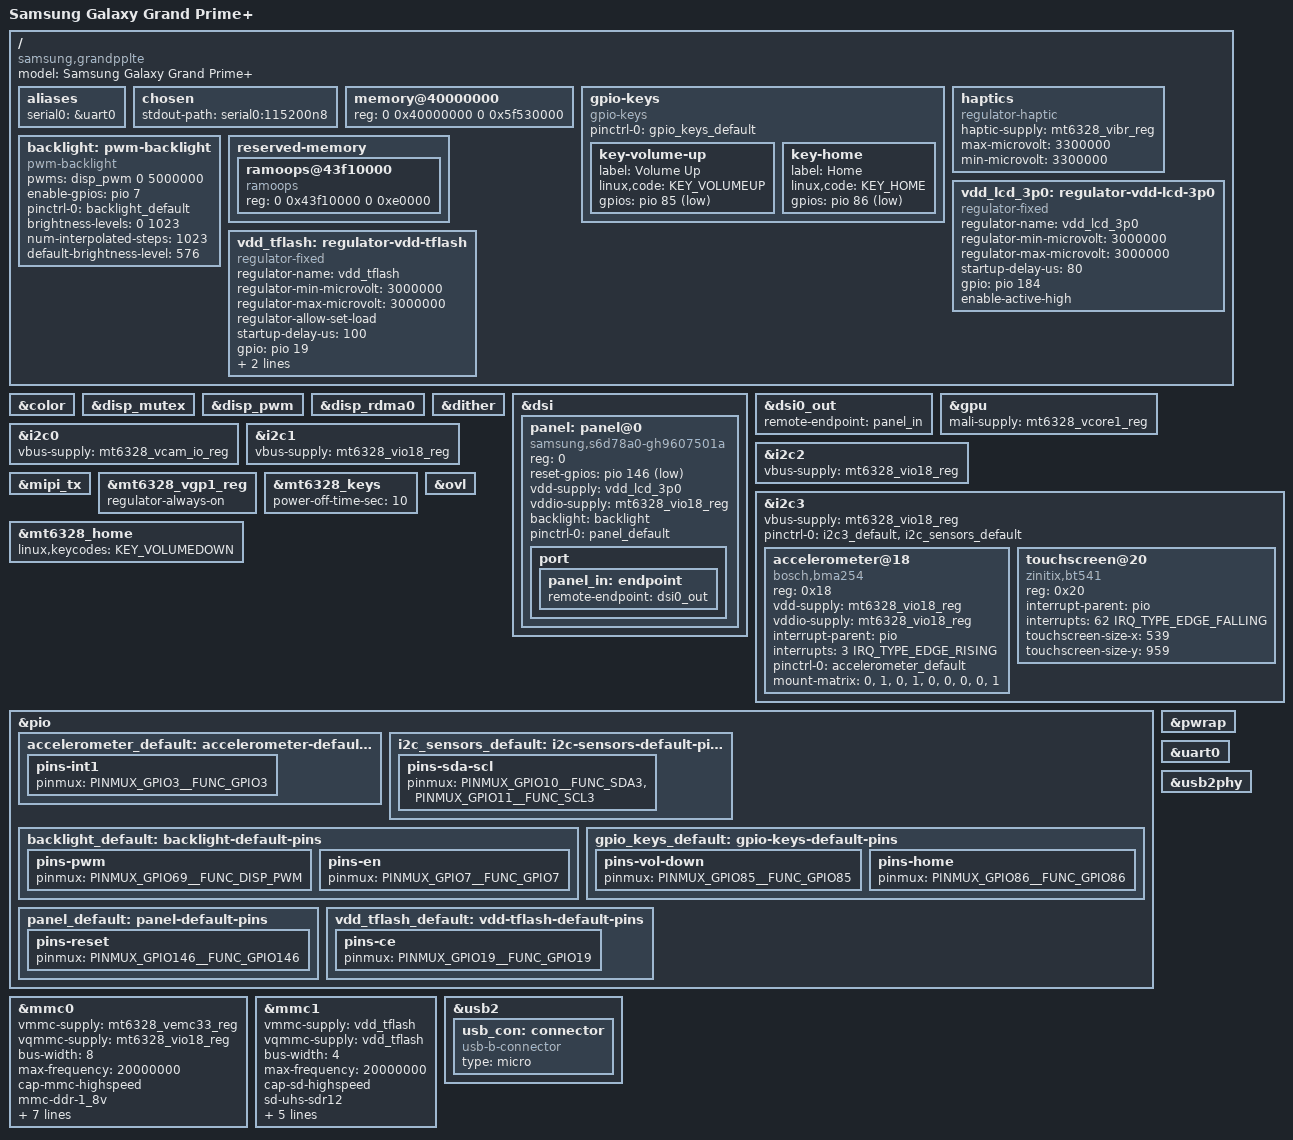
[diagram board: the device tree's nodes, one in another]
// SPDX-License-Identifier: BSD-3-Clause
/*
 * Copyright (c) 2021, Yassine Oudjana <y.oudjana@protonmail.com>
 */

/dts-v1/;

#include "mt6735.dtsi"
#include "mt6328.dtsi"
#include <dt-bindings/gpio/gpio.h>
#include <dt-bindings/input/input.h>
#include <dt-bindings/pinctrl/mediatek,mt6735-pinctrl.h>

/ {
	model = "Samsung Galaxy Grand Prime+";
	compatible = "samsung,grandpplte",
		     "mediatek,mt6737t",
		     "mediatek,mt6735";

	aliases {
		serial0 = &uart0;
	};

	chosen {
		#address-cells = <2>;
		#size-cells = <2>;
		ranges;

		stdout-path = "serial0:115200n8";
	};

	memory@40000000 {
		device_type = "memory";
		reg = <0 0x40000000 0 0x5f530000>;
	};

	gpio-keys {
		compatible = "gpio-keys";

		pinctrl-names = "default";
		pinctrl-0 = <&gpio_keys_default>;

		key-volume-up {
			label = "Volume Up";
			linux,code = <KEY_VOLUMEUP>;
			gpios = <&pio 85 GPIO_ACTIVE_LOW>;
		};

		key-home {
			label = "Home";
			linux,code = <KEY_HOME>;
			gpios = <&pio 86 GPIO_ACTIVE_LOW>;
		};
	};

	haptics {
		compatible = "regulator-haptic";
		haptic-supply = <&mt6328_vibr_reg>;
		max-microvolt = <3300000>;
		min-microvolt = <3300000>;
	};

	backlight: pwm-backlight {
		compatible = "pwm-backlight";

		pwms = <&disp_pwm 0 5000000>;
		enable-gpios = <&pio 7 GPIO_ACTIVE_HIGH>;

		pinctrl-names = "default";
		pinctrl-0 = <&backlight_default>;

		brightness-levels = <0 1023>;
		num-interpolated-steps = <1023>;
		default-brightness-level = <576>;
	};

	reserved-memory {
		ramoops@43f10000 {
			compatible = "ramoops";
			reg = <0 0x43f10000 0 0xe0000>;
		};
	};

	vdd_lcd_3p0: regulator-vdd-lcd-3p0 {
		compatible = "regulator-fixed";
		regulator-name = "vdd_lcd_3p0";
		regulator-min-microvolt = <3000000>;
		regulator-max-microvolt = <3000000>;
		startup-delay-us = <80>;
		gpio = <&pio 184 0>;
		enable-active-high;
	};

	vdd_tflash: regulator-vdd-tflash {
		compatible = "regulator-fixed";
		regulator-name = "vdd_tflash";
		regulator-min-microvolt = <3000000>;
		regulator-max-microvolt = <3000000>;
		regulator-allow-set-load;
		startup-delay-us = <100>;
		gpio = <&pio 19 0>;
		enable-active-high;

		pinctrl-names = "default";
		pinctrl-0 = <&vdd_tflash_default>;
	};
};

&color {
	status = "okay";
};

&disp_mutex {
	status = "okay";
};

&disp_pwm {
	status = "okay";
};

&disp_rdma0 {
	status = "okay";
};

&dither {
	status = "okay";
};

&dsi {
	status = "okay";

	panel: panel@0 {
		compatible = "samsung,s6d78a0-gh9607501a";
		reg = <0>;

		reset-gpios = <&pio 146 GPIO_ACTIVE_LOW>;

		vdd-supply = <&vdd_lcd_3p0>;
		vddio-supply = <&mt6328_vio18_reg>;

		backlight = <&backlight>;

		pinctrl-names = "default";
		pinctrl-0 = <&panel_default>;

		port {
			panel_in: endpoint {
				remote-endpoint = <&dsi0_out>;
			};
		};
	};
};

&dsi0_out {
	remote-endpoint = <&panel_in>;
};

&gpu {
	status = "okay";

	mali-supply = <&mt6328_vcore1_reg>;
};

&i2c0 {
	status = "okay";

	vbus-supply = <&mt6328_vcam_io_reg>;
};

&i2c1 {
	status = "okay";

	vbus-supply = <&mt6328_vio18_reg>;
};

&i2c2 {
	status = "okay";

	vbus-supply = <&mt6328_vio18_reg>;
};

&i2c3 {
	status = "okay";

	vbus-supply = <&mt6328_vio18_reg>;

	pinctrl-names = "default";
	pinctrl-0 = <&i2c3_default>, <&i2c_sensors_default>;

	accelerometer@18 {
		compatible = "bosch,bma254";
		reg = <0x18>;

		vdd-supply = <&mt6328_vio18_reg>;
		vddio-supply = <&mt6328_vio18_reg>;

		interrupt-parent = <&pio>;
		interrupts = <3 IRQ_TYPE_EDGE_RISING>;
		interrupt-names = "INT1";

		pinctrl-names = "default";
		pinctrl-0 = <&accelerometer_default>;

		mount-matrix = "0", "1", "0",
				"1", "0", "0",
				"0", "0", "1";
	};

	touchscreen@20 {
		compatible = "zinitix,bt541";
		reg = <0x20>;
		interrupt-parent = <&pio>;
		interrupts = <62 IRQ_TYPE_EDGE_FALLING>;

		touchscreen-size-x = <539>;
		touchscreen-size-y = <959>;
	};
};

&mipi_tx {
	status = "okay";
};

/* Touchscreen supply. TODO: Add regulator handling to zinitix driver */
&mt6328_vgp1_reg {
	regulator-always-on;
};

&mt6328_keys {
	status = "okay";

	power-off-time-sec = <10>;
};

&mt6328_home {
	linux,keycodes = <KEY_VOLUMEDOWN>;
};

&ovl {
	status = "okay";
};

&pio {
	accelerometer_default: accelerometer-default-pins {
		pins-int1 {
			pinmux = <PINMUX_GPIO3__FUNC_GPIO3>;
		};
	};

	i2c_sensors_default: i2c-sensors-default-pins {
		pins-sda-scl {
			pinmux = <PINMUX_GPIO10__FUNC_SDA3>,
				 <PINMUX_GPIO11__FUNC_SCL3>;
		};
	};

	backlight_default: backlight-default-pins {
		pins-pwm {
			pinmux = <PINMUX_GPIO69__FUNC_DISP_PWM>;
		};

		pins-en {
			pinmux = <PINMUX_GPIO7__FUNC_GPIO7>;
		};
	};

	gpio_keys_default: gpio-keys-default-pins {
		pins-vol-down {
			pinmux = <PINMUX_GPIO85__FUNC_GPIO85>;
		};

		pins-home {
			pinmux = <PINMUX_GPIO86__FUNC_GPIO86>;
		};
	};

	panel_default: panel-default-pins {
		pins-reset {
			pinmux = <PINMUX_GPIO146__FUNC_GPIO146>;
		};
	};

	vdd_tflash_default: vdd-tflash-default-pins {
		pins-ce {
			pinmux = <PINMUX_GPIO19__FUNC_GPIO19>;
		};
	};
};

&pwrap {
	status = "okay";
};

&mmc0 {
	status = "okay";

	vmmc-supply = <&mt6328_vemc33_reg>;
	vqmmc-supply = <&mt6328_vio18_reg>;

	bus-width = <8>;
	max-frequency = <20000000>;
	cap-mmc-highspeed;
	mmc-ddr-1_8v;
	mmc-hs200-1_8v;
	/* TODO: Fix tuning issue in HS400 mode */
	// mmc-hs400-1_8v;
	non-removable;

	mediatek,hs200-cmd-int-delay = <11>;
	mediatek,hs400-cmd-int-delay = <6>;
	mediatek,hs400-cmd-resp-sel-rising;
	mediatek,hs400-ds-dly3 = <10>;
	mediatek,latch-ck = <1>;
};

/* TODO: Fix microSD card slot. Possibly a power issue. */
&mmc1 {
	status = "okay";

	vmmc-supply = <&vdd_tflash>;
	vqmmc-supply = <&vdd_tflash>;

	bus-width = <4>;
	max-frequency = <20000000>;
	cap-sd-highspeed;
	sd-uhs-sdr12;
	sd-uhs-sdr25;
	sd-uhs-sdr50;
	sd-uhs-sdr104;
	sd-uhs-ddr50;

	cd-gpios = <&pio 5 GPIO_ACTIVE_LOW>;
};

/*
 * UART accessible through USB micro-B port with 619k resistor
 * connected between ID and GND. TX on D+, RX on D-.
 */
&uart0 {
	status = "okay";
};

&usb2 {
	status = "okay";

	usb_con: connector {
		compatible = "usb-b-connector";
		type = "micro";
	};
};

&usb2phy {
	status = "okay";
};
